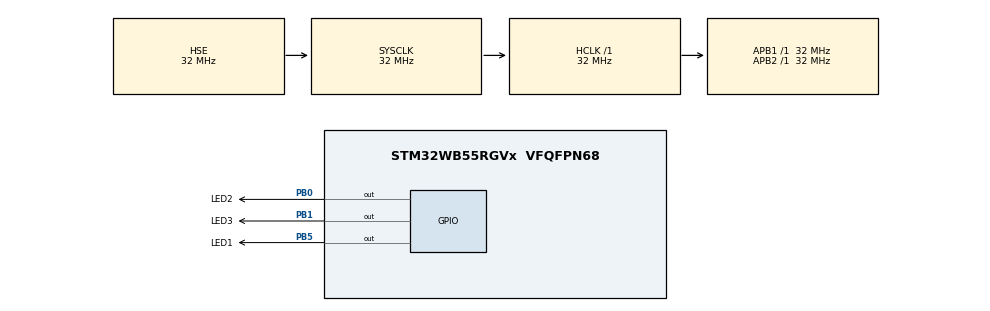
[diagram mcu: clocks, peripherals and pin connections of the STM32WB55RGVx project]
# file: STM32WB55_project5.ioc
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Mcu.Family=STM32WB
Mcu.Name=STM32WB55RGVx
Mcu.Package=VFQFPN68
NVIC.HSEM_IRQn=true\:0\:0\:false\:false\:true\:false\:true\:true
NVIC.IPCC_C1_RX_IRQn=true\:0\:0\:false\:false\:true\:true\:true\:true
NVIC.IPCC_C1_TX_IRQn=true\:0\:0\:false\:false\:true\:true\:true\:true
NVIC.PriorityGroup=NVIC_PRIORITYGROUP_4
OSC_IN.Mode=HSE-External-Oscillator
OSC_IN.Signal=RCC_OSC_IN
OSC_OUT.Mode=HSE-External-Oscillator
OSC_OUT.Signal=RCC_OSC_OUT
PB0.GPIO_Label=LED2
PB0.Signal=GPIO_Output
PB1.GPIO_Label=LED3
PB1.Signal=GPIO_Output
PB5.GPIO_Label=LED1
PB5.Signal=GPIO_Output
PC14-OSC32_IN.Mode=LSE-External-Oscillator
PC14-OSC32_IN.Signal=RCC_OSC32_IN
PC15-OSC32_OUT.Mode=LSE-External-Oscillator
PC15-OSC32_OUT.Signal=RCC_OSC32_OUT
ProjectManager.HeapSize=0x200
ProjectManager.StackSize=0x400
ProjectManager.TargetToolchain=MDK-ARM V5.32
RCC.AHBFreq_Value=32000000
RCC.APB1Freq_Value=32000000
RCC.APB1TimFreq_Value=32000000
RCC.APB2Freq_Value=32000000
RCC.APB2TimFreq_Value=32000000
RCC.APB3Freq_Value=16000000
RCC.CortexFreq_Value=32000000
RCC.HCLKFreq_Value=32000000
RCC.HSE_VALUE=32000000
RCC.HSI48_VALUE=48000000
RCC.HSI_VALUE=16000000
RCC.RFWKPClockSelection=RCC_RFWKPCLKSOURCE_LSE
RCC.RTCClockSelection=RCC_RTCCLKSOURCE_LSE
RCC.SYSCLKFreq_VALUE=32000000
RCC.SYSCLKSource=RCC_SYSCLKSOURCE_HSE
RCC.VCOOutputFreq_Value=32000000
RF1.Mode=RF1_Activate
RF1.Signal=RF_RF1
STM32_WPAN.AD_TYPE_COMPLETE_LOCAL_NAME=myDevice
STM32_WPAN.CFG_LSCLK_LSE=0
STM32_WPAN.CUSTOM_P2P_SERVER=Disabled
STM32_WPAN.CUSTOM_TEMPLATE=Enabled
STM32_WPAN.INCLUDE_AD_TYPE_COMPLETE_LOCAL_NAME=1
STM32_WPAN.NUMBER_OF_SERVICES=1
STM32_WPAN.SERVICE1_CHAR1_LONG_NAME=myCharWrite
STM32_WPAN.SERVICE1_CHAR1_SHORT_NAME=myCharWrite
STM32_WPAN.SERVICE1_LONG_NAME=mySVC
STM32_WPAN.SERVICE1_SHORT_NAME=mySVC
VP_HSEM_VS_HSEM.Mode=HSEM_Activate
VP_IPCC_VS_IPCC.Mode=IPCC_Activate
VP_MEMORYMAP_VS_MEMORYMAP.Mode=CurAppReg
VP_RTC_VS_RTC_Activate.Mode=RTC_Enabled
VP_RTC_VS_RTC_WakeUp_intern.Mode=WakeUp
VP_SEQUENCER_VS_SEQUENCER.Mode=SEQUENCER_Enabled
VP_STM32_WPAN_VS_BLE_HOST.Mode=STM32_WPAN_Enabled
VP_TINY_LPM_VS_TINY_LPM.Mode=TINY_LPM_Enabled
board=custom

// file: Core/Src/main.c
/* USER CODE BEGIN Header */
/**
  ******************************************************************************
  * @file           : main.c
  * @brief          : Main program body
  ******************************************************************************
  * @attention
  *
  * Copyright (c) 2024 STMicroelectronics.
  * All rights reserved.
  *
  * This software is licensed under terms that can be found in the LICENSE file
  * in the root directory of this software component.
  * If no LICENSE file comes with this software, it is provided AS-IS.
  *
  ******************************************************************************
  */
/* USER CODE END Header */
#include "main.h"
#include "ipcc.h"
#include "memorymap.h"
#include "rf.h"
#include "rtc.h"
#include "gpio.h"

void SystemClock_Config(void);
void PeriphCommonClock_Config(void);

int main(void)
{

  /* MCU Configuration--------------------------------------------------------*/

  /* Reset of all peripherals, Initializes the Flash interface and the Systick. */
  HAL_Init();
  /* Config code for STM32_WPAN (HSE Tuning must be done before system clock configuration) */
  MX_APPE_Config();

  /* Configure the system clock */
  SystemClock_Config();

  /* Configure the peripherals common clocks */
  PeriphCommonClock_Config();

  /* IPCC initialisation */
  MX_IPCC_Init();

  /* Initialize all configured peripherals */
  MX_GPIO_Init();
  MX_RTC_Init();
  MX_RF_Init();
  /* USER CODE BEGIN 2 */
	HAL_GPIO_WritePin(LED1_GPIO_Port, LED1_Pin, GPIO_PIN_SET);
	HAL_GPIO_WritePin(LED2_GPIO_Port, LED2_Pin, GPIO_PIN_SET);
  /* USER CODE END 2 */

  /* Init code for STM32_WPAN */
  MX_APPE_Init();

  /* Infinite loop */
  while (1)
  {
    MX_APPE_Process();

  }
}

void SystemClock_Config(void)
{
  RCC_OscInitTypeDef RCC_OscInitStruct = {0};
  RCC_ClkInitTypeDef RCC_ClkInitStruct = {0};

  /** Configure LSE Drive Capability
  */
  HAL_PWR_EnableBkUpAccess();
  __HAL_RCC_LSEDRIVE_CONFIG(RCC_LSEDRIVE_MEDIUMHIGH);

  /** Configure the main internal regulator output voltage
  */
  __HAL_PWR_VOLTAGESCALING_CONFIG(PWR_REGULATOR_VOLTAGE_SCALE1);

  /** Initializes the RCC Oscillators according to the specified parameters
  * in the RCC_OscInitTypeDef structure.
  */
  RCC_OscInitStruct.OscillatorType = RCC_OSCILLATORTYPE_HSI|RCC_OSCILLATORTYPE_HSE
                              |RCC_OSCILLATORTYPE_LSE;
  RCC_OscInitStruct.HSEState = RCC_HSE_ON;
  RCC_OscInitStruct.LSEState = RCC_LSE_ON;
  RCC_OscInitStruct.HSIState = RCC_HSI_ON;
  RCC_OscInitStruct.HSICalibrationValue = RCC_HSICALIBRATION_DEFAULT;
  RCC_OscInitStruct.PLL.PLLState = RCC_PLL_NONE;
  if (HAL_RCC_OscConfig(&RCC_OscInitStruct) != HAL_OK)
  {
    Error_Handler();
  }

  /** Configure the SYSCLKSource, HCLK, PCLK1 and PCLK2 clocks dividers
  */
  RCC_ClkInitStruct.ClockType = RCC_CLOCKTYPE_HCLK4|RCC_CLOCKTYPE_HCLK2
                              |RCC_CLOCKTYPE_HCLK|RCC_CLOCKTYPE_SYSCLK
                              |RCC_CLOCKTYPE_PCLK1|RCC_CLOCKTYPE_PCLK2;
  RCC_ClkInitStruct.SYSCLKSource = RCC_SYSCLKSOURCE_HSE;
  RCC_ClkInitStruct.AHBCLKDivider = RCC_SYSCLK_DIV1;
  RCC_ClkInitStruct.APB1CLKDivider = RCC_HCLK_DIV1;
  RCC_ClkInitStruct.APB2CLKDivider = RCC_HCLK_DIV1;
  RCC_ClkInitStruct.AHBCLK2Divider = RCC_SYSCLK_DIV1;
  RCC_ClkInitStruct.AHBCLK4Divider = RCC_SYSCLK_DIV1;

  if (HAL_RCC_ClockConfig(&RCC_ClkInitStruct, FLASH_LATENCY_1) != HAL_OK)
  {
    Error_Handler();
  }
}

void PeriphCommonClock_Config(void)
{
  RCC_PeriphCLKInitTypeDef PeriphClkInitStruct = {0};

  /** Initializes the peripherals clock
  */
  PeriphClkInitStruct.PeriphClockSelection = RCC_PERIPHCLK_SMPS|RCC_PERIPHCLK_RFWAKEUP;
  PeriphClkInitStruct.RFWakeUpClockSelection = RCC_RFWKPCLKSOURCE_LSE;
  PeriphClkInitStruct.SmpsClockSelection = RCC_SMPSCLKSOURCE_HSI;
  PeriphClkInitStruct.SmpsDivSelection = RCC_SMPSCLKDIV_RANGE1;

  if (HAL_RCCEx_PeriphCLKConfig(&PeriphClkInitStruct) != HAL_OK)
  {
    Error_Handler();
  }
}

void Error_Handler(void)
{
  __disable_irq();
  while (1)
  {
  }
}
